# D register map
File version: 1
Registers are 8-bit, read-write, no defined reset value unless marked. A register's access mark holds for its fields unless they carry their own. Offsets are from the block's base; lines under a group give offsets from that group; [hi:lo] are bit positions; {n}, {i} and the like mark numbered series; 'fields as' and 'values as' point back to an identical list; <NAME> marks a mode.

## Memory map
0x00001000 P

## P
Base 0x00001000
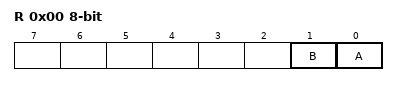
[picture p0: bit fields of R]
0x00 R
  [1] B, [0] A
